# PIC32MK0128MCA028 device description
Architecture: MIPS; Family: PIC32MK; Series: PIC32MK
Registers are 32-bit, read-write, no defined reset value unless marked. A register's access mark holds for its fields unless they carry their own. Offsets are from the block's base; [hi:lo] are bit positions; {n}, {i} and the like mark numbered series; 'fields as' and 'values as' point back to an identical list.

## CMP
Instances: CMP 0x1f82c000 in periph_pb2_std
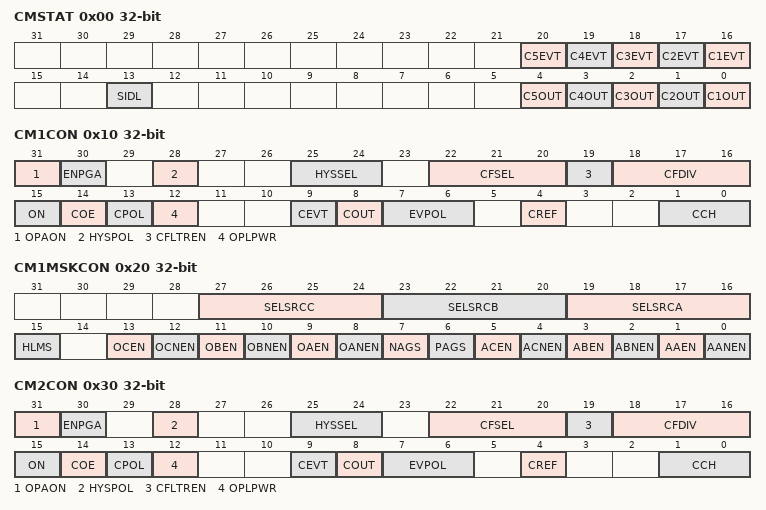
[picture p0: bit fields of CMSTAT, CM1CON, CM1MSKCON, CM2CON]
0x00 CMSTAT — Op amp/Comparator Status Register
  [n+15] C{n}EVT (n=1..5) — Comparator {n} Event Status bit
    1=Comparator event according to EVPOL settings occurred. Future events/triggers and interrupts are disabled until the CEVT bit (CMxCON) is cleared by user software.; 0=Comparator event did not occur
  [13] SIDL — Stop in Idle Mode bit
    1=Discontinue operation of all Op amp/Comparators when device enters Idle mode; 0=Continue module operation in Idle mode
  [n-1] C{n}OUT (n=1..5) — Op amp/Comparator {n} Output Status bit
    1=(When CPOL is 0) Vin+ greater than Vth+ / (When CPOL is 1) VIN+ Vth+ / (When CPOL is 1) VIN+ less than VTH-; 0=(When CPOL is 0) Vin+ Vth+
0x10 CM1CON — Op amp/Comparator x Control Register
  [31] OPAON — Opamp Enable Bit
    1=Op amp enabled and connected to pin; 0=Op amp disabled and pin is released to other functions
  [30] ENPGA — Opamp Fixed Gain Enable bit
    1=Op amp is operating in Fixed Gain 1X mode; 0=Op amp is operating in Open Loop mode (default)
  [28] HYSPOL — Comparator Hysteresis Polarity Selection
    1=Hysteresis on falling edge, rising edge is accurate; 0=Hysteresis on rising edge, falling edge is accurate
  [25:24] HYSSEL — Hysteresis Selection bits
    3=Set highest hysteresis level (Typical 45 mV); 2=Set medium hysteresis level (Typical 30 mV); 1=Set lowest hysteresis level (Typical 15 mV); 0=No hysteresis selected
  [22:20] CFSEL — Comparator Output Filter Clock Source Select bits
    {v}=PBCLK2/Timer{v-2} Period Value (PR{v-2}) (v=4..7); 3=REFCLK3 Clock; 2=PWM Secondary Special Event; 1=PPBCLK2 Clock; 0=SYSCLK Clock
  [19] CFLTREN — Comparator Output Digital Filter Enable bit
    1=Digital Filters enabled; 0=Digital Filters disabled
  [18:16] CFDIV — Comparator Output Filter Clock Divide Select bits
    7=1:128 Clock Divide; 6=1:64 Clock Divide; 5=1:32 Clock Divide; 4=1:16 Clock Divide; 3=1:8 Clock Divide; 2=1:4 Clock Divide; 1=1:2 Clock Divide; 0=1:1 Clock Divide
  [15] ON — Comparator Enable bit
    1=Comparator is enabled; 0=Comparator is disabled
  [14] COE — Comparator Output Enable bit
    1=Comparator output is present on the CxOUT pin; 0=Comparator output is internal only
  [13] CPOL — Comparator Output Polarity Select bit
    1=Comparator output is inverted; 0=Comparator output is not inverted
  [12] OPLPWR — Op-Amp Power mode
    1=Op-amp operating in low power mode (1/10 power, slower response, Bandwidth = 10Mhz); 0=Op-amp operating in normal power mode, (10Mhz = Bandwidth = 100Mhz)
  [9] CEVT — Comparator Event bit
    1=Comparator event according to EVPOL bit settings occurred; 0=Comparator event did not occur
  [8] COUT — Comparator Output bit
    1=(When CPOL is 0) VIN+ greater than VTH+ / (When CPOL is 1) VIN+ VTH+ / (When CPOL is 1) VIN+ less than VTH-; 0=(When CPOL is 0) VIN+ VTH-
  [7:6] EVPOL — Trigger/Event Polarity Select bits
    3=Trigger/Event generated on any change of the comparator output; 2=(When CPOL is 0) Trigger/Event generated only on high-to-low transition of the polarity-selected comparator output / (When CPOL is 1) Trigger/Event generated only on low-to-high transition of the polarity-selected comparator output; 1=(When CPOL is 0) Trigger/Event generated only on low-to-high transition of the polarity-selected comparator output / (When CPOL is 1) Trigger/Event generated only on high-to-low transition of the polarity-selected comparator output; 0=Trigger/Event generation is disabled
  [4] CREF — Op amp/Comparator Reference Select bit
    1=VIN+ input connects to internal CDAC2 output voltage; 0=VIN+ input connects to CxIN1+ pin
  [1:0] CCH — Comparator Channel Select bits
    {v}=CxIN{v+1}- (v=0..3)
0x20 CM1MSKCON — Comparator x Mask Control Register
  [27:24] SELSRCC — Mask C Input Select bits
    15=FLT4 pin; 14=FLT2 pin; {v}=PWM{v-8}L (v=9..13); {v}=PWM{v+1}H (v=0..8)
  [23:20] SELSRCB — Mask B Input Select bits
    values as SELSRCC
  [19:16] SELSRCA — Mask A Input Select bits
    values as SELSRCC
  [15] HLMS — High or Low Level Masking Select bit
    1=The comparator deasserted state is 1; 0=The comparator deasserted state is 0
  [13] OCEN — OR Gate C Input Enable bit
    1=C input enabled as input to OR gate; 0=C input disabled as input to OR gate
  [12] OCNEN — OR Gate C Input Inverted Enable bit
    1=C input (inverted) enabled as input to OR gate; 0=C input (inverted) disabled as input to OR gate
  [11] OBEN — OR Gate B Input Enable bit
    1=B input enabled as input to OR gate; 0=B input disabled as input to OR gate
  [10] OBNEN — OR Gate B Input Inverted Enable bit
    1=B input (inverted) enabled as input to OR gate; 0=B input (inverted) disabled as input to OR gate
  [9] OAEN — OR Gate A Input Enable bit
    1=A input enabled as input to OR gate; 0=A input disabled as input to OR gate
  [8] OANEN — OR Gate A Input Inverted Enable bit
    1=A input (inverted) enabled as input to OR gate; 0=A input (inverted) disabled as input to OR gate
  [7] NAGS — Negative AND Gate Output Select bit
    1=The negative (inverted) output of the AND gate to the OR gate is enabled; 0=The negative (inverted) output of the AND gate to the OR gate is disabled
  [6] PAGS — Positive AND Gate Output Select bit
    1=The positive output of the AND gate to the OR gate is enabled; 0=The positive output of the AND gate to the OR gate is disabled
  [5] ACEN — AND Gate C Input Enable bit
    1=C input enabled as input to AND gate; 0=C input disabled as input to AND gate
  [4] ACNEN — AND Gate C Inverted Input Enable bit
    1=C input (inverted) enabled as input to AND gate; 0=C input (inverted) disabled as input to AND gate
  [3] ABEN — AND Gate B Input Enable bit
    1=B input enabled as input to AND gate; 0=B input disabled as input to AND gate
  [2] ABNEN — AND Gate B Inverted Input Enable bit
    1=B input (inverted) enabled as input to AND gate; 0=B input (inverted) disabled as input to AND gate
  [1] AAEN — AND Gate A Input Enable bit
    1=A input enabled as input to AND gate; 0=A input disabled as input to AND gate
  [0] AANEN — AND Gate A Inverted Input Enable bit
    1=A input (inverted) enabled as input to AND gate; 0=A input (inverted) disabled as input to AND gate
0x30 CM2CON — Op amp/Comparator x Control Register
  fields as CM1CON
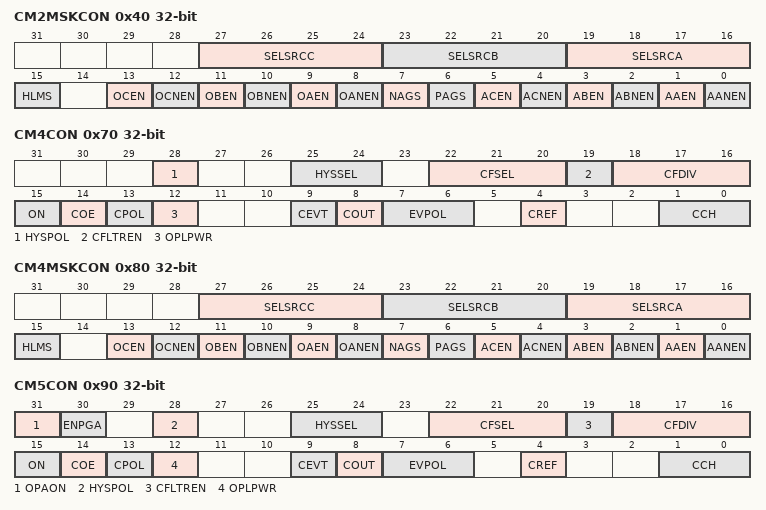
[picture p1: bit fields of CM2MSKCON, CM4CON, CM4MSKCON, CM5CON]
0x40 CM2MSKCON — Comparator x Mask Control Register
  fields as CM1MSKCON
0x70 CM4CON — Op amp/Comparator x Control Register
  [28] HYSPOL — Comparator Hysteresis Polarity Selection
  [25:24] HYSSEL — Hysteresis Selection bits
  [22:20] CFSEL — Comparator Output Filter Clock Source Select bits
  [19] CFLTREN — Comparator Output Digital Filter Enable bit
  [18:16] CFDIV — Comparator Output Filter Clock Divide Select bits
  [15] ON — Comparator Enable bit
  [14] COE — Comparator Output Enable bit
  [13] CPOL — Comparator Output Polarity Select bit
  [12] OPLPWR — Op-Amp Power mode
  [9] CEVT — Comparator Event bit
  [8] COUT — Comparator Output bit
  [7:6] EVPOL — Trigger/Event Polarity Select bits
  [4] CREF — Op amp/Comparator Reference Select bit
  [1:0] CCH — Comparator Channel Select bits
0x80 CM4MSKCON — Comparator x Mask Control Register
  [27:24] SELSRCC — Mask C Input Select bits
  [23:20] SELSRCB — Mask B Input Select bits
  [19:16] SELSRCA — Mask A Input Select bits
  [15] HLMS — High or Low Level Masking Select bit
  [13] OCEN — OR Gate C Input Enable bit
  [12] OCNEN — OR Gate C Input Inverted Enable bit
  [11] OBEN — OR Gate B Input Enable bit
  [10] OBNEN — OR Gate B Input Inverted Enable bit
  [9] OAEN — OR Gate A Input Enable bit
  [8] OANEN — OR Gate A Input Inverted Enable bit
  [7] NAGS — Negative AND Gate Output Select bit
  [6] PAGS — Positive AND Gate Output Select bit
  [5] ACEN — AND Gate C Input Enable bit
  [4] ACNEN — AND Gate C Inverted Input Enable bit
  [3] ABEN — AND Gate B Input Enable bit
  [2] ABNEN — AND Gate B Inverted Input Enable bit
  [1] AAEN — AND Gate A Input Enable bit
  [0] AANEN — AND Gate A Inverted Input Enable bit
0x90 CM5CON — Op amp/Comparator x Control Register
  [31] OPAON — Opamp Enable Bit
  [30] ENPGA — Opamp Fixed Gain Enable bit
  [28] HYSPOL — Comparator Hysteresis Polarity Selection
  [25:24] HYSSEL — Hysteresis Selection bits
  [22:20] CFSEL — Comparator Output Filter Clock Source Select bits
  [19] CFLTREN — Comparator Output Digital Filter Enable bit
  [18:16] CFDIV — Comparator Output Filter Clock Divide Select bits
  [15] ON — Comparator Enable bit
  [14] COE — Comparator Output Enable bit
  [13] CPOL — Comparator Output Polarity Select bit
  [12] OPLPWR — Op-Amp Power mode
  [9] CEVT — Comparator Event bit
  [8] COUT — Comparator Output bit
  [7:6] EVPOL — Trigger/Event Polarity Select bits
  [4] CREF — Op amp/Comparator Reference Select bit
  [1:0] CCH — Comparator Channel Select bits
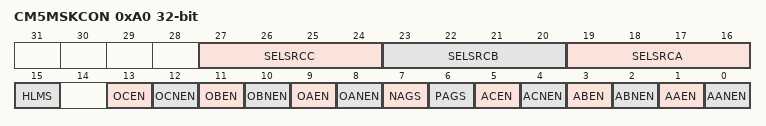
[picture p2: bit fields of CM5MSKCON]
0xA0 CM5MSKCON — Comparator x Mask Control Register
  fields as CM4MSKCON

## Notices in the file
Copyright (c) 2019 Microchip Technology Inc.
SPDX-License-Identifier: Apache-2.0
Licensed under the Apache License, Version 2.0 (the "License");
you may not use this file except in compliance with the License.
You may obtain a copy of the License at
http://www.apache.org/licenses/LICENSE-2.0
Unless required by applicable law or agreed to in writing, software
distributed under the License is distributed on an "AS IS" BASIS,
WITHOUT WARRANTIES OR CONDITIONS OF ANY KIND, either express or implied.
See the License for the specific language governing permissions and
limitations under the License.
